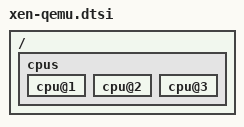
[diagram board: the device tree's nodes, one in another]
/ {
        cpus {
                cpu@1 {
                        //compatible = "disabled";
                        device_type = "none";
                };
                cpu@2 {
                        //compatible = "disabled";
                        device_type = "none";
                };
                cpu@3 {
                        //compatible = "disabled";
                        device_type = "none";
                };
        };
};
